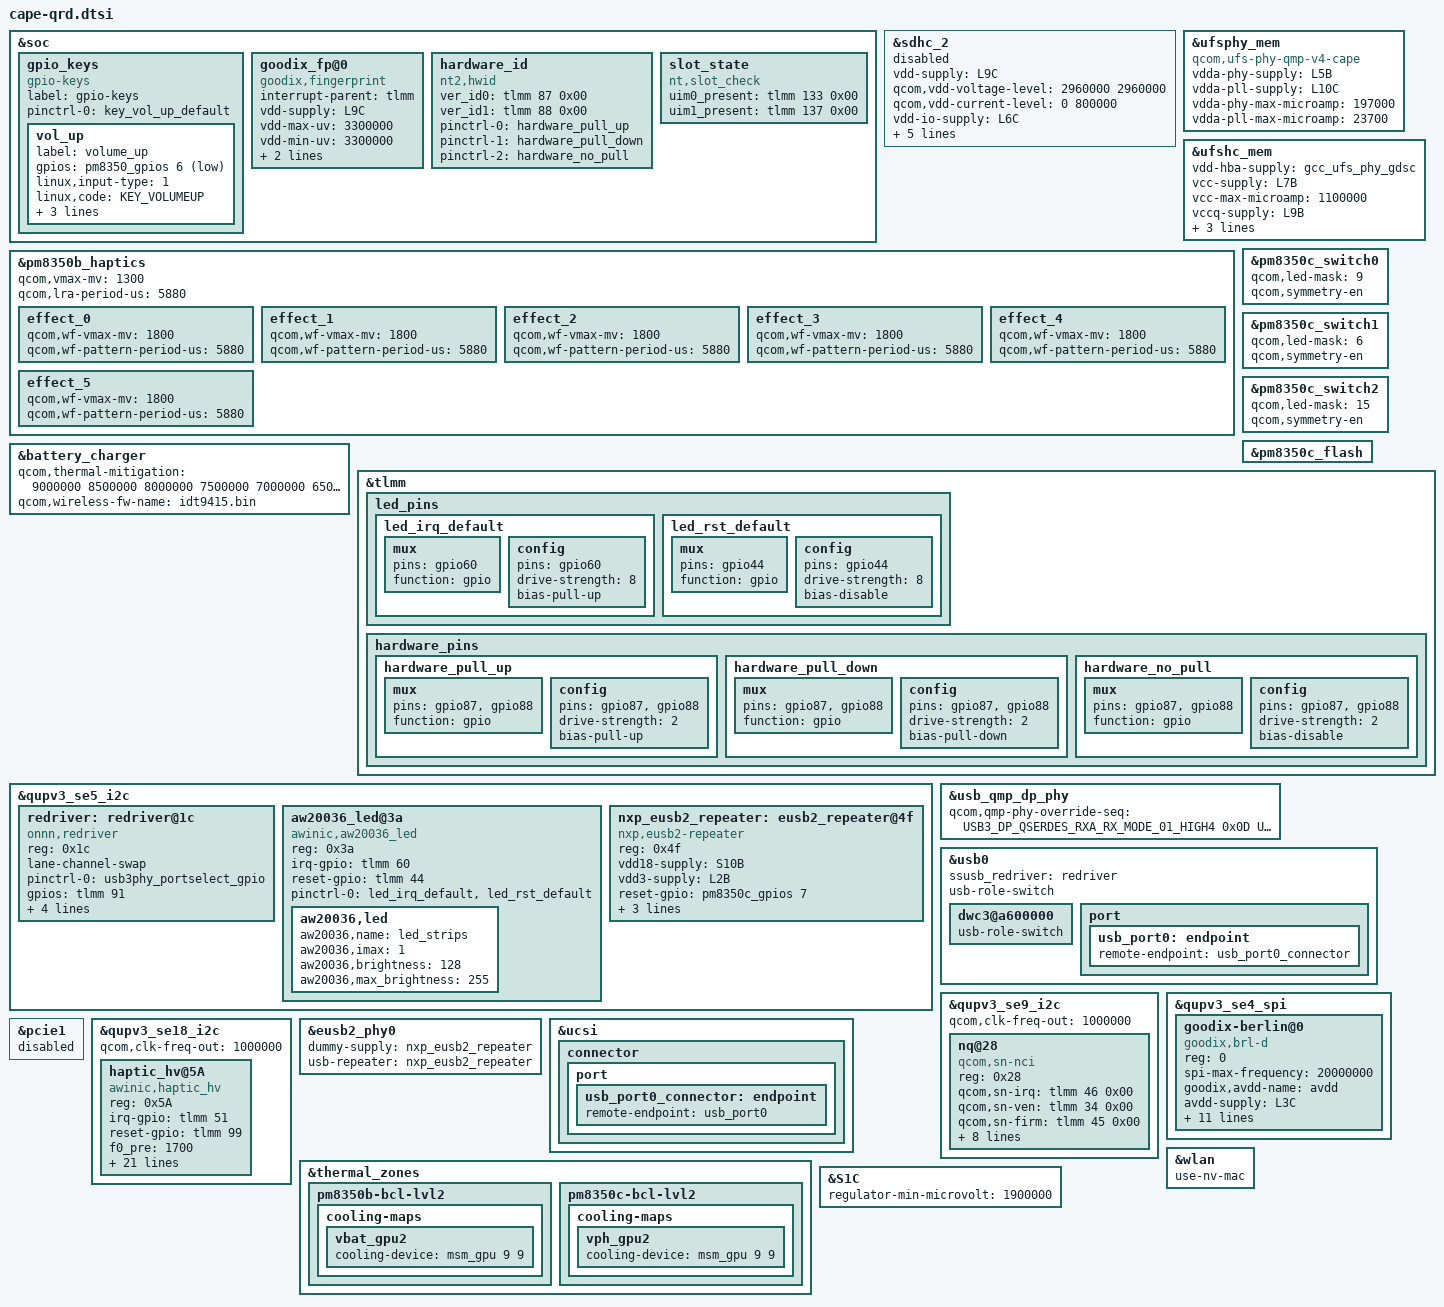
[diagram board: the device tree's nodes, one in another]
#include <dt-bindings/gpio/gpio.h>
#include <dt-bindings/input/input.h>
#include "cape-pmic-overlay.dtsi"
#include "waipio-thermal-overlay.dtsi"
#include <dt-bindings/phy/qcom,usb3-4nm-qmp-combo.h>

&soc {
	gpio_keys {
		compatible = "gpio-keys";
		label = "gpio-keys";

		pinctrl-names = "default";
		pinctrl-0 = <&key_vol_up_default>;

		vol_up {
			label = "volume_up";
			gpios = <&pm8350_gpios 6 GPIO_ACTIVE_LOW>;
			linux,input-type = <1>;
			linux,code = <KEY_VOLUMEUP>;
			gpio-key,wakeup;
			debounce-interval = <15>;
			linux,can-disable;
		};
	};

	goodix_fp@0 {
		compatible = "goodix,fingerprint";
		interrupt-parent = <&tlmm>;
		vdd-supply = <&L9C>;
		vdd-max-uv = <3300000>;
		vdd-min-uv = <3300000>;
		fp-gpio-irq = <&tlmm 40 0x00>;
		fp-gpio-reset = <&tlmm 41 0x00>;
		status = "ok";
	};
};

&sdhc_2 {
	status = "disabled";
	vdd-supply = <&L9C>;
	qcom,vdd-voltage-level = <2960000 2960000>;
	qcom,vdd-current-level = <0 800000>;

	vdd-io-supply = <&L6C>;
	qcom,vdd-io-voltage-level = <1800000 2960000>;
	qcom,vdd-io-current-level = <0 125000>;

	pinctrl-names = "default", "sleep";
	pinctrl-0 = <&sdc2_on>;
	pinctrl-1 = <&sdc2_off>;

	cd-gpios = <&tlmm 92 GPIO_ACTIVE_LOW>;
};

&ufsphy_mem {
	compatible = "qcom,ufs-phy-qmp-v4-cape";

	vdda-phy-supply = <&L5B>;
	vdda-pll-supply = <&L10C>;
	vdda-phy-max-microamp = <197000>;
	vdda-pll-max-microamp = <23700>;

	status = "ok";
};

&ufshc_mem {
	vdd-hba-supply = <&gcc_ufs_phy_gdsc>;

	vcc-supply = <&L7B>;
	vcc-max-microamp = <1100000>;

	vccq-supply = <&L9B>;
	vccq-max-microamp = <1200000>;

	qcom,vddp-ref-clk-supply = <&L9B>;
	qcom,vddp-ref-clk-max-microamp = <100>;

	status = "ok";
};

&pm8350b_haptics {
	qcom,vmax-mv = <1300>;
	qcom,lra-period-us = <5880>;
	status = "ok";

	effect_0 {
		/* CLICK */
		qcom,wf-vmax-mv = <1800>;
		qcom,wf-pattern-period-us = <5880>;
	};

	effect_1 {
		/* DOUBLE_CLICK */
		qcom,wf-vmax-mv = <1800>;
		qcom,wf-pattern-period-us = <5880>;
	};

	effect_2 {
		/* TICK */
		qcom,wf-vmax-mv = <1800>;
		qcom,wf-pattern-period-us = <5880>;
	};

	effect_3 {
		/* THUD */
		qcom,wf-vmax-mv = <1800>;
		qcom,wf-pattern-period-us = <5880>;
	};

	effect_4 {
		/* POP */
		qcom,wf-vmax-mv = <1800>;
		qcom,wf-pattern-period-us = <5880>;
	};

	effect_5 {
		/* HEAVY CLICK */
		qcom,wf-vmax-mv = <1800>;
		qcom,wf-pattern-period-us = <5880>;
	};
};

&pm8350c_switch0 {
	qcom,led-mask = <9>; /* Channels 1 & 4 */
	qcom,symmetry-en;
};

&pm8350c_switch1 {
	qcom,led-mask = <6>; /* Channels 2 & 3 */
	qcom,symmetry-en;
};

&pm8350c_switch2 {
	qcom,led-mask = <15>; /* All Channels */
	qcom,symmetry-en;
};

&pm8350c_flash {
	status = "ok";
};

&battery_charger {
	qcom,thermal-mitigation = <9000000 8500000 8000000 7500000 7000000 6500000
				6000000 5500000 5000000 4500000 4000000 3500000
				3000000 2500000 2400000 2000000 1600000 1500000 1200000 1000000 500000 0>;
	qcom,wireless-fw-name = "idt9415.bin";
	#cooling-cells = <2>;
};

&tlmm {
	led_pins {
		led_irq_default: led_irq_default {
			mux {
				pins = "gpio60";
				function = "gpio";
			};

			config {
				pins = "gpio60";
				drive-strength = <8>;
				bias-pull-up;
			};
		};

		led_rst_default: led_rst_default {
			mux {
				pins = "gpio44";
				function = "gpio";
			};

			config {
				pins = "gpio44";
				drive-strength = <8>;
				bias-disable;
			};
		};
	};
};

&qupv3_se5_i2c {
	status = "ok";

	#address-cells = <1>;
	#size-cells = <0>;
	redriver: redriver@1c {
		compatible = "onnn,redriver";
		reg = <0x1c>;

		lane-channel-swap;

		pinctrl-names = "default";
		pinctrl-0 = <&usb3phy_portselect_gpio>;
		gpios = <&tlmm 91 0>;

		eq = /bits/ 8 <
				/* Parameters for USB */
				0x4 0x4 0x4 0x4
				/* Parameters for DP */
				0x4 0x6 0x6 0x4>;
		flat-gain = /bits/ 8 <
				/* Parameters for USB */
				0x0 0x1 0x1 0x2
				/* Parameters for DP */
				0x0 0x3 0x3 0x0>;
		output-comp = /bits/ 8 <
				/* Parameters for USB */
				0x3 0x3 0x3 0x3
				/* Parameters for DP */
				0x3 0x3 0x3 0x3>;
		loss-match = /bits/ 8 <
				/* Parameters for USB */
				0x1 0x3 0x3 0x1
				/* Parameters for DP */
				0x3 0x3 0x3 0x3>;
	};

	aw20036_led@3a {
		compatible = "awinic,aw20036_led";
		reg = <0x3a>;
		irq-gpio = <&tlmm 60 0>;
		reset-gpio = <&tlmm 44 0>;
		pinctrl-names = "default";
		pinctrl-0 = <&led_irq_default &led_rst_default>;
		status = "okay";
		aw20036,led {
			aw20036,name = "led_strips";
			aw20036,imax = <1>;
			aw20036,brightness = <128>;
			aw20036,max_brightness = <255>;
		};
	};
};

&usb_qmp_dp_phy {
	pinctrl-names = "unused";

	qcom,qmp-phy-override-seq =
		/* <reg_offset,	value> */
		<USB3_DP_QSERDES_RXA_RX_MODE_01_HIGH4		0x0D
		USB3_DP_QSERDES_TXB_TX_DRV_LVL			0x38
		USB3_DP_QSERDES_RXB_RX_MODE_01_HIGH4		0x0D>;
};

&usb0 {
	ssusb_redriver = <&redriver>;
};

&qupv3_se9_i2c {
	status = "ok";
	qcom,clk-freq-out = <1000000>;
	#address-cells = <1>;
	#size-cells = <0>;
	nq@28 {
		compatible = "qcom,sn-nci";
		reg = <0x28>;
		qcom,sn-irq = <&tlmm 46 0x00>;
		qcom,sn-ven = <&tlmm 34 0x00>;
		qcom,sn-firm = <&tlmm 45 0x00>;
		qcom,sn-clkreq = <&tlmm 35 0x00>;
		qcom,sn-vdd-1p8-supply = <&S10B>;
		qcom,sn-vdd-1p8-voltage = <1800000 1800000>;
		qcom,sn-vdd-1p8-current = <157000>;
		interrupt-parent = <&tlmm>;
		interrupts = <46 0>;
		interrupt-names = "nfc_irq";
		pinctrl-names = "nfc_active", "nfc_suspend";
		pinctrl-0 = <&nfc_int_active &nfc_enable_active>;
		pinctrl-1 = <&nfc_int_suspend &nfc_enable_suspend>;
	};
};

&qupv3_se4_spi {
	status = "ok";

	goodix-berlin@0 {
		compatible = "goodix,brl-d";
		reg = <0>;
		spi-max-frequency = <20000000>;

		goodix,avdd-name = "avdd";
		avdd-supply = <&L3C>;
		goodix,iovdd-name = "iovdd";
		iovdd-supply = <&L12C>;

		goodix,reset-gpio = <&tlmm 20 0x0>;
		goodix,irq-gpio = <&tlmm 21 0x2008>;
		goodix,irq-flags = <2>; /* 1:trigger rising, 2:trigger falling; */
		goodix,panel-max-x = <1080>;
		goodix,panel-max-y = <2412>;
		goodix,panel-max-w = <255>;

		/* optional properties */
		goodix,sleep-enable; /* enter sleep mode */
		goodix,firmware-name = "goodix_firmware.bin";
		goodix,config-name = "goodix_cfg_group.bin";
	};

};

&qupv3_se5_i2c {
	status = "ok";

	#address-cells = <1>;
	#size-cells = <0>;
	nxp_eusb2_repeater: eusb2_repeater@4f {
		compatible = "nxp,eusb2-repeater";
		reg = <0x4f>;
		vdd18-supply = <&S10B>;
		vdd3-supply = <&L2B>;
		reset-gpio = <&pm8350c_gpios 7 GPIO_ACTIVE_HIGH>;
		pinctrl-names = "default";
		pinctrl-0 = <&eusb2_reset_ctrl_default>;
		qcom,param-override-seq =
				/* Rx squelch detection threshold to 110mV; default is 125mV */
				<0x40 0x06
				/*
				 * Tx Deemphasis to 2dB, Tx Deemphasis bit duration to 0.8UI;
				 * default is 0 for both
				 */
				0x22 0x07
				/* Output Voltage Swing to 550mV; default is 450mV */
				0x64 0x08>;
	};
};


&pcie1 {
	status = "disabled";
};

&qupv3_se18_i2c {
	status = "ok";
	qcom,clk-freq-out = <1000000>;
	#address-cells = <1>;
	#size-cells = <0>;

	haptic_hv@5A{
		compatible = "awinic,haptic_hv";
		reg = <0x5A>;
		irq-gpio = <&tlmm 51 0>;
		reset-gpio = <&tlmm 99 0>;
		f0_pre = < 1700 >;
		mode = /bits/ 8 < 5 >;
		f0_cali_percent = /bits/ 8 < 7 >;

		/*************aw8692x***************/
		aw8692x_gain_bypass = /bits/ 8 < 1 >;
		aw8692x_cont_drv1_lvl = /bits/ 8 < 0x7F >;
		aw8692x_cont_lra_vrms = < 1000 >; /* Motor rated voltage, mV */
		aw8692x_cont_drv1_time = /bits/ 8 < 0x04 >;
		aw8692x_cont_drv2_time = /bits/ 8 < 0x06 >;
		aw8692x_cont_wait_num = /bits/ 8 < 0x06 >;
		aw8692x_cont_brk_time = /bits/ 8 < 0x08 >;
		aw8692x_cont_track_margin = /bits/ 8 < 0x0F >;
		aw8692x_brk_bst_md = /bits/ 8 < 0 >;
		aw8692x_cont_tset = /bits/ 8 < 0x06 >;
		aw8692x_cont_bemf_set = /bits/ 8 < 0x02 >;
		aw8692x_cont_bst_brk_gain = /bits/ 8 < 0x05 >;
		aw8692x_cont_brk_gain = /bits/ 8 < 0x08 >;
		aw8692x_duration_time = /bits/ 8 < 20 30 60 >;
		aw8692x_d2s_gain = /bits/ 8 < 0x04 >;
		aw8692x_trig_config = /bits/ 8 < 0 0 0 1 0 2 0 0
						 0 0 0 1 0 2 0 0
						 0 0 0 1 0 2 0 0 >;
		aw8692x_bst_vol_default = < 9000 >;
		aw8692x_is_enabled_track_en;
		/* aw8692x_is_enabled_auto_bst; */
		/* aw8692x_is_enabled_one_wire; */
	};
};

&tlmm {
	hardware_pins {
		hardware_pull_up: hardware_pull_up {
			mux {
				pins = "gpio87", "gpio88";
				function = "gpio";
			};

			config {
				pins = "gpio87", "gpio88";
				drive-strength = <2>;
				bias-pull-up;
			};
		};

		hardware_pull_down: hardware_pull_down {
			mux {
				pins = "gpio87", "gpio88";
				function = "gpio";
			};

			config {
				pins = "gpio87", "gpio88";
				drive-strength = <2>;
				bias-pull-down;
			};
		};


		hardware_no_pull: hardware_no_pull {
			mux {
				pins = "gpio87", "gpio88";
				function = "gpio";
			};

			config {
				pins = "gpio87", "gpio88";
				drive-strength = <2>;
				bias-disable;
			};
		};


	};

};

&soc {
        hardware_id {
		compatible = "nt2,hwid";
		ver_id0 = <&tlmm 87 0x00>;
		ver_id1 = <&tlmm 88 0x00>;
		pinctrl-names = "hardware_up", "hardware_down", "hardware_lpm";
		pinctrl-0 = <&hardware_pull_up>;
		pinctrl-1 = <&hardware_pull_down>;
		pinctrl-2 = <&hardware_no_pull>;
		status = "okay";
        };

	slot_state {
		compatible = "nt,slot_check";
		uim0_present = <&tlmm 133 0x00>;
		uim1_present = <&tlmm 137 0x00>;
	};
};

&eusb2_phy0 {
	dummy-supply = <&nxp_eusb2_repeater>;
	usb-repeater = <&nxp_eusb2_repeater>;
};

&usb0 {
	usb-role-switch;

	dwc3@a600000 {
		usb-role-switch;
	};

	port {
		usb_port0: endpoint {
			remote-endpoint = <&usb_port0_connector>;
		};
	};
};

&ucsi {
	connector {
		port {
			usb_port0_connector: endpoint {
				remote-endpoint = <&usb_port0>;
			};
		};
	};
};

&thermal_zones {
	pm8350b-bcl-lvl2 {
		cooling-maps {
			vbat_gpu2 {
				cooling-device = <&msm_gpu 9 9>;
			};
		};
	};

	pm8350c-bcl-lvl2 {
		cooling-maps {
			vph_gpu2 {
				cooling-device = <&msm_gpu 9 9>;
			};
		};
	};
};

&wlan {
       use-nv-mac;
};

&S1C {
	regulator-min-microvolt = <1900000>;
};
